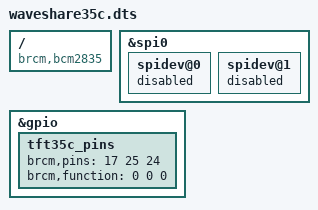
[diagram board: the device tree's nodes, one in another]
/dts-v1/;
/plugin/;

/ {
  compatible = "brcm,bcm2835", "brcm,bcm2708", "brcm,bcm2709";
};

&spi0 {
  status = "okay";
  spidev@0 {
    status = "disabled";
  };
  spidev@1 {
    status = "disabled";
  };
};

&gpio {
  tft35c_pins: tft35c_pins {
    brcm,pins = <17 25 24>;
    brcm,function = <0 0 0>; /* in in in */
  }
};

&spi0 {
  #address-cells = <1>;
  #size-cells = <0>;
}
